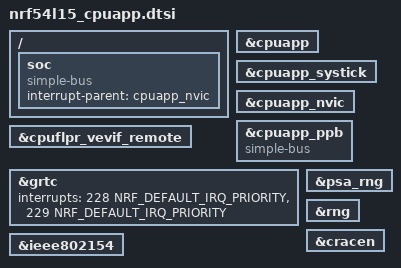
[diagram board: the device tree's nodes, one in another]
/*
 * Copyright (c) 2024 Nordic Semiconductor ASA
 *
 * SPDX-License-Identifier: Apache-2.0
 */

#include <nordic/nrf54l15.dtsi>

cpu: &cpuapp {};
systick: &cpuapp_systick {};
nvic: &cpuapp_nvic {};
cpuflpr_vevif: &cpuflpr_vevif_remote {};

/delete-node/ &cpuflpr;
/delete-node/ &cpuflpr_rram;
/delete-node/ &cpuflpr_sram;
/delete-node/ &cpuflpr_clic;

/ {
	soc {
		compatible = "simple-bus";
		interrupt-parent = <&cpuapp_nvic>;
		ranges;
	};
};

&cpuapp_ppb {
	compatible = "simple-bus";
	ranges;
};

&grtc {
	interrupts = <228 NRF_DEFAULT_IRQ_PRIORITY>,
			<229 NRF_DEFAULT_IRQ_PRIORITY>; /* MPSL uses the GRTC_3_IRQn */
};

&ieee802154 {
	status = "okay";
};

&psa_rng {
	status = "okay";
};

&rng {
	status = "okay";
};

&cracen {
	status = "okay";
};
